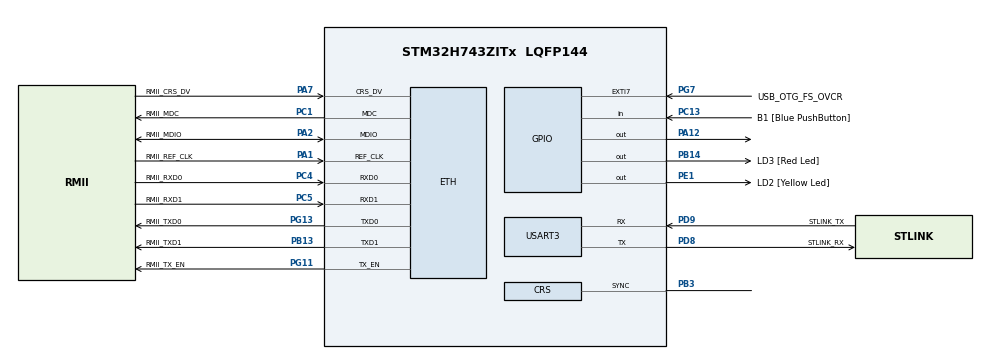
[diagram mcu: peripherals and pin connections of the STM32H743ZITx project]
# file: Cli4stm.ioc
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CORTEX_M7.AccessPermission-Cortex_Memory_Protection_Unit_Region0_Settings=MPU_REGION_FULL_ACCESS
CORTEX_M7.AccessPermission-Cortex_Memory_Protection_Unit_Region1_Settings=MPU_REGION_FULL_ACCESS
CORTEX_M7.BaseAddress-Cortex_Memory_Protection_Unit_Region0_Settings=0x30040000
CORTEX_M7.BaseAddress-Cortex_Memory_Protection_Unit_Region1_Settings=0x30040000
CORTEX_M7.CPU_DCache=Enabled
CORTEX_M7.CPU_ICache=Enabled
CORTEX_M7.DisableExec-Cortex_Memory_Protection_Unit_Region0_Settings=MPU_INSTRUCTION_ACCESS_DISABLE
CORTEX_M7.DisableExec-Cortex_Memory_Protection_Unit_Region1_Settings=MPU_INSTRUCTION_ACCESS_DISABLE
CORTEX_M7.Enable-Cortex_Memory_Protection_Unit_Region0_Settings=MPU_REGION_ENABLE
CORTEX_M7.Enable-Cortex_Memory_Protection_Unit_Region1_Settings=MPU_REGION_ENABLE
CORTEX_M7.IsBufferable-Cortex_Memory_Protection_Unit_Region1_Settings=MPU_ACCESS_BUFFERABLE
CORTEX_M7.IsShareable-Cortex_Memory_Protection_Unit_Region1_Settings=MPU_ACCESS_SHAREABLE
CORTEX_M7.MPU_Control=MPU_PRIVILEGED_DEFAULT
CORTEX_M7.Size-Cortex_Memory_Protection_Unit_Region0_Settings=MPU_REGION_SIZE_32KB
CORTEX_M7.Size-Cortex_Memory_Protection_Unit_Region1_Settings=MPU_REGION_SIZE_256B
CORTEX_M7.TypeExtField-Cortex_Memory_Protection_Unit_Region0_Settings=MPU_TEX_LEVEL1
ETH.MediaInterface=HAL_ETH_RMII_MODE
FREERTOS.Queues01=queueRxUart3,64,uint8_t,0,Static,rxUart3Buffer,rxUart3ControlBlock
FREERTOS.Tasks01=defaultTask,0,256,StartDefaultTask,Default,NULL,Dynamic,NULL,NULL;cliSerialTask,-3,256,StartCliTaskSerial,As external,&huart3,Dynamic,NULL,NULL;cliUdpTask,-3,256,StartCliTaskUdp,As external,NULL,Dynamic,NULL,NULL
FREERTOS.configENABLE_FPU=0
FREERTOS.configMINIMAL_STACK_SIZE=256
FREERTOS.configTOTAL_HEAP_SIZE=100000
FREERTOS.configUSE_NEWLIB_REENTRANT=1
FREERTOS.configUSE_PREEMPTION=1
LWIP.BSP.number=1
LWIP.GATEWAY_ADDRESS=192.168.014.001
LWIP.IP_ADDRESS=192.168.014.002
LWIP.LWIP_DHCP=0
LWIP.MEM_SIZE=1600
LWIP.NETMASK_ADDRESS=255.255.255.000
LWIP.Version=v2.1.2_Cube
LWIP0.BSP.STBoard=false
LWIP0.BSP.api=BSP_COMPONENT_DRIVER
LWIP0.BSP.component=LAN8742
LWIP0.BSP.i2caddr=0
LWIP0.BSP.instance=LAN8742
LWIP0.BSP.name=Driver_PHY
LWIP0.BSP.solution=LAN8742
Mcu.Family=STM32H7
Mcu.Name=STM32H743ZITx
Mcu.Package=LQFP144
Mcu.UserConstants=_GNU_SOURCE,1
NVIC.ETH_IRQn=true\:5\:0\:false\:false\:true\:true\:true\:true
NVIC.EXTI9_5_IRQn=true\:5\:0\:false\:false\:true\:true\:true\:true
NVIC.PriorityGroup=NVIC_PRIORITYGROUP_4
NVIC.TIM17_IRQn=true\:0\:0\:false\:false\:true\:false\:false\:true
NVIC.TimeBase=TIM17_IRQn
NVIC.TimeBaseIP=TIM17
NVIC.USART3_IRQn=true\:5\:0\:false\:false\:true\:true\:true\:true
PA1.GPIO_Label=RMII_REF_CLK
PA1.GPIO_Speed=GPIO_SPEED_FREQ_VERY_HIGH
PA1.Mode=RMII
PA1.Signal=ETH_REF_CLK
PA12.Signal=GPIO_Output
PA2.GPIO_Label=RMII_MDIO
PA2.GPIO_Speed=GPIO_SPEED_FREQ_VERY_HIGH
PA2.Mode=RMII
PA2.Signal=ETH_MDIO
PA7.GPIO_Label=RMII_CRS_DV
PA7.GPIO_Speed=GPIO_SPEED_FREQ_VERY_HIGH
PA7.Mode=RMII
PA7.Signal=ETH_CRS_DV
PB13.GPIO_Label=RMII_TXD1
PB13.GPIO_Speed=GPIO_SPEED_FREQ_VERY_HIGH
PB13.Mode=RMII
PB13.Signal=ETH_TXD1
PB14.GPIO_Label=LD3 [Red Led]
PB14.GPIO_Speed=GPIO_SPEED_FREQ_VERY_HIGH
PB14.PinState=GPIO_PIN_RESET
PB14.Signal=GPIO_Output
PB3\ (JTDO/TRACESWO).Mode=CRS SYNC Source GPIO
PB3\ (JTDO/TRACESWO).Signal=CRS_SYNC
PC1.GPIO_Label=RMII_MDC
PC1.GPIO_Speed=GPIO_SPEED_FREQ_LOW
PC1.Mode=RMII
PC1.Signal=ETH_MDC
PC13.GPIO_Label=B1 [Blue PushButton]
PC13.Signal=GPIO_Input
PC14-OSC32_IN\ (OSC32_IN).Mode=LSE-External-Oscillator
PC14-OSC32_IN\ (OSC32_IN).Signal=RCC_OSC32_IN
PC15-OSC32_OUT\ (OSC32_OUT).Mode=LSE-External-Oscillator
PC15-OSC32_OUT\ (OSC32_OUT).Signal=RCC_OSC32_OUT
PC4.GPIO_Label=RMII_RXD0
PC4.GPIO_Speed=GPIO_SPEED_FREQ_VERY_HIGH
PC4.Mode=RMII
PC4.Signal=ETH_RXD0
PC5.GPIO_Label=RMII_RXD1
PC5.GPIO_Speed=GPIO_SPEED_FREQ_VERY_HIGH
PC5.Mode=RMII
PC5.Signal=ETH_RXD1
PD8.GPIO_Label=STLINK_RX
PD8.Mode=Asynchronous
PD8.Signal=USART3_TX
PD9.GPIO_Label=STLINK_TX
PD9.Mode=Asynchronous
PD9.Signal=USART3_RX
PE1.GPIO_Label=LD2 [Yellow Led]
PE1.GPIO_Speed=GPIO_SPEED_FREQ_VERY_HIGH
PE1.Signal=GPIO_Output
PG11.GPIO_Label=RMII_TX_EN
PG11.GPIO_Speed=GPIO_SPEED_FREQ_VERY_HIGH
PG11.Mode=RMII
PG11.Signal=ETH_TX_EN
PG13.GPIO_Label=RMII_TXD0
PG13.GPIO_Speed=GPIO_SPEED_FREQ_VERY_HIGH
PG13.Mode=RMII
PG13.Signal=ETH_TXD0
PG7.GPIO_Label=USB_OTG_FS_OVCR
PG7.Signal=GPXTI7
PH0-OSC_IN\ (PH0).GPIO_Label=MCO
PH0-OSC_IN\ (PH0).Mode=HSE-External-Oscillator
PH0-OSC_IN\ (PH0).Signal=RCC_OSC_IN
PH1-OSC_OUT\ (PH1).Mode=HSE-External-Oscillator
PH1-OSC_OUT\ (PH1).Signal=RCC_OSC_OUT
ProjectManager.HeapSize=0x200
ProjectManager.StackSize=0x400
ProjectManager.TargetToolchain=STM32CubeIDE
RCC.ADCFreq_Value=129000000
RCC.APB1Freq_Value=100000000
RCC.APB2Freq_Value=100000000
RCC.APB3Freq_Value=100000000
RCC.APB4Freq_Value=100000000
RCC.CortexFreq_Value=400000000
RCC.D1PPRE=RCC_APB3_DIV2
RCC.D2PPRE1=RCC_APB1_DIV2
RCC.D2PPRE2=RCC_APB2_DIV2
RCC.D3PPRE=RCC_APB4_DIV2
RCC.DIVM1=4
RCC.DIVN1=50
RCC.DIVQ1=4
RCC.HCLKFreq_Value=200000000
RCC.HPRE=RCC_HCLK_DIV2
RCC.HSE_VALUE=25000000
RCC.PLL2FRACN=0
RCC.PLL3FRACN=0
RCC.PLLFRACN=0
RCC.PLLSourceVirtual=RCC_PLLSOURCE_HSI
RCC.PWR_Regulator_Voltage_Scale=PWR_REGULATOR_VOLTAGE_SCALE1
RCC.SYSCLKFreq_VALUE=400000000
RCC.SYSCLKSource=RCC_SYSCLKSOURCE_PLLCLK
RCC.USBFreq_Value=200000000
USART3.VirtualMode-Asynchronous=VM_ASYNC
VP_FREERTOS_VS_CMSIS_V1.Mode=CMSIS_V1
VP_HRTIM_VS_hrtimMasterTimerNoOutput.Mode=MasterTimer
VP_LWIP_VS_Enabled.Mode=Enabled
VP_SYS_VS_tim17.Mode=TIM17
board=NUCLEO-H743ZI2

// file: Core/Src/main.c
/* USER CODE BEGIN Header */
/**
  ******************************************************************************
  * @file           : main.c
  * @brief          : Main program body
  ******************************************************************************
  * @attention
  *
  * <h2><center>&copy; Copyright (c) 2021 STMicroelectronics.
  * All rights reserved.</center></h2>
  *
  * This software component is licensed by ST under BSD 3-Clause license,
  * the "License"; You may not use this file except in compliance with the
  * License. You may obtain a copy of the License at:
  *                        opensource.org/licenses/BSD-3-Clause
  *
  ******************************************************************************
  */
/* USER CODE END Header */
#include "main.h"
#include "cmsis_os.h"
#include "lwip.h"
#include "cliTaskTcp.h"

HRTIM_HandleTypeDef hhrtim;

UART_HandleTypeDef huart3;

osThreadId defaultTaskHandle;
osThreadId cliSerialTaskHandle;
osThreadId cliUdpTaskHandle;
osMessageQId queueRxUart3Handle;
uint8_t rxUart3Buffer[ 64 * sizeof( uint8_t ) ];
osStaticMessageQDef_t rxUart3ControlBlock;

void SystemClock_Config(void);
static void MPU_Config(void);
static void MX_GPIO_Init(void);
static void MX_USART3_UART_Init(void);
static void MX_HRTIM_Init(void);
void StartDefaultTask(void const * argument);
extern void StartCliTaskSerial(void const * argument);
extern void StartCliTaskUdp(void const * argument);

int main(void)
{

  /* MPU Configuration--------------------------------------------------------*/
  MPU_Config();

  /* Enable I-Cache---------------------------------------------------------*/
  SCB_EnableICache();

  /* Enable D-Cache---------------------------------------------------------*/
  SCB_EnableDCache();

  /* MCU Configuration--------------------------------------------------------*/

  /* Reset of all peripherals, Initializes the Flash interface and the Systick. */
  HAL_Init();

  /* Configure the system clock */
  SystemClock_Config();

  /* Initialize all configured peripherals */
  MX_GPIO_Init();
  MX_USART3_UART_Init();
  MX_HRTIM_Init();

  /* Create the queue(s) */
  /* definition and creation of queueRxUart3 */
  osMessageQStaticDef(queueRxUart3, 64, uint8_t, rxUart3Buffer, &rxUart3ControlBlock);
  queueRxUart3Handle = osMessageCreate(osMessageQ(queueRxUart3), NULL);

  /* Create the thread(s) */
  /* definition and creation of defaultTask */
  osThreadDef(defaultTask, StartDefaultTask, osPriorityNormal, 0, 256);
  defaultTaskHandle = osThreadCreate(osThread(defaultTask), NULL);

  /* definition and creation of cliSerialTask */
  osThreadDef(cliSerialTask, StartCliTaskSerial, osPriorityIdle, 0, 256);
  cliSerialTaskHandle = osThreadCreate(osThread(cliSerialTask), (void*) &huart3);

  /* definition and creation of cliUdpTask */
  osThreadDef(cliUdpTask, StartCliTaskUdp, osPriorityIdle, 0, 256);
  cliUdpTaskHandle = osThreadCreate(osThread(cliUdpTask), NULL);

  /* Start scheduler */
  osKernelStart();

  /* We should never get here as control is now taken by the scheduler */
  /* Infinite loop */
  while (1)
  {

  }
}

void SystemClock_Config(void)
{
  RCC_OscInitTypeDef RCC_OscInitStruct = {0};
  RCC_ClkInitTypeDef RCC_ClkInitStruct = {0};
  RCC_CRSInitTypeDef RCC_CRSInitStruct = {0};

  /** Supply configuration update enable
  */
  HAL_PWREx_ConfigSupply(PWR_LDO_SUPPLY);
  /** Configure the main internal regulator output voltage
  */
  __HAL_PWR_VOLTAGESCALING_CONFIG(PWR_REGULATOR_VOLTAGE_SCALE1);

  while(!__HAL_PWR_GET_FLAG(PWR_FLAG_VOSRDY)) {}
  /** Initializes the RCC Oscillators according to the specified parameters
  * in the RCC_OscInitTypeDef structure.
  */
  RCC_OscInitStruct.OscillatorType = RCC_OSCILLATORTYPE_HSI48|RCC_OSCILLATORTYPE_HSI;
  RCC_OscInitStruct.HSIState = RCC_HSI_DIV1;
  RCC_OscInitStruct.HSICalibrationValue = RCC_HSICALIBRATION_DEFAULT;
  RCC_OscInitStruct.HSI48State = RCC_HSI48_ON;
  RCC_OscInitStruct.PLL.PLLState = RCC_PLL_ON;
  RCC_OscInitStruct.PLL.PLLSource = RCC_PLLSOURCE_HSI;
  RCC_OscInitStruct.PLL.PLLM = 4;
  RCC_OscInitStruct.PLL.PLLN = 50;
  RCC_OscInitStruct.PLL.PLLP = 2;
  RCC_OscInitStruct.PLL.PLLQ = 4;
  RCC_OscInitStruct.PLL.PLLR = 2;
  RCC_OscInitStruct.PLL.PLLRGE = RCC_PLL1VCIRANGE_3;
  RCC_OscInitStruct.PLL.PLLVCOSEL = RCC_PLL1VCOWIDE;
  RCC_OscInitStruct.PLL.PLLFRACN = 0;
  if (HAL_RCC_OscConfig(&RCC_OscInitStruct) != HAL_OK)
  {
    Error_Handler();
  }
  /** Initializes the CPU, AHB and APB buses clocks
  */
  RCC_ClkInitStruct.ClockType = RCC_CLOCKTYPE_HCLK|RCC_CLOCKTYPE_SYSCLK
                              |RCC_CLOCKTYPE_PCLK1|RCC_CLOCKTYPE_PCLK2
                              |RCC_CLOCKTYPE_D3PCLK1|RCC_CLOCKTYPE_D1PCLK1;
  RCC_ClkInitStruct.SYSCLKSource = RCC_SYSCLKSOURCE_PLLCLK;
  RCC_ClkInitStruct.SYSCLKDivider = RCC_SYSCLK_DIV1;
  RCC_ClkInitStruct.AHBCLKDivider = RCC_HCLK_DIV2;
  RCC_ClkInitStruct.APB3CLKDivider = RCC_APB3_DIV2;
  RCC_ClkInitStruct.APB1CLKDivider = RCC_APB1_DIV2;
  RCC_ClkInitStruct.APB2CLKDivider = RCC_APB2_DIV2;
  RCC_ClkInitStruct.APB4CLKDivider = RCC_APB4_DIV2;

  if (HAL_RCC_ClockConfig(&RCC_ClkInitStruct, FLASH_LATENCY_2) != HAL_OK)
  {
    Error_Handler();
  }
  /** Enable the SYSCFG APB clock
  */
  __HAL_RCC_CRS_CLK_ENABLE();
  /** Configures CRS
  */
  RCC_CRSInitStruct.Prescaler = RCC_CRS_SYNC_DIV1;
  RCC_CRSInitStruct.Source = RCC_CRS_SYNC_SOURCE_PIN;
  RCC_CRSInitStruct.Polarity = RCC_CRS_SYNC_POLARITY_RISING;
  RCC_CRSInitStruct.ReloadValue = __HAL_RCC_CRS_RELOADVALUE_CALCULATE(48000000,1);
  RCC_CRSInitStruct.ErrorLimitValue = 34;
  RCC_CRSInitStruct.HSI48CalibrationValue = 32;

  HAL_RCCEx_CRSConfig(&RCC_CRSInitStruct);
}

static void MX_HRTIM_Init(void)
{

  HRTIM_TimeBaseCfgTypeDef pTimeBaseCfg = {0};
  HRTIM_TimerCfgTypeDef pTimerCfg = {0};

  hhrtim.Instance = HRTIM1;
  hhrtim.Init.HRTIMInterruptResquests = HRTIM_IT_NONE;
  hhrtim.Init.SyncOptions = HRTIM_SYNCOPTION_NONE;
  if (HAL_HRTIM_Init(&hhrtim) != HAL_OK)
  {
    Error_Handler();
  }
  pTimeBaseCfg.Period = 0xFFFD;
  pTimeBaseCfg.RepetitionCounter = 0x00;
  pTimeBaseCfg.PrescalerRatio = HRTIM_PRESCALERRATIO_DIV1;
  pTimeBaseCfg.Mode = HRTIM_MODE_CONTINUOUS;
  if (HAL_HRTIM_TimeBaseConfig(&hhrtim, HRTIM_TIMERINDEX_MASTER, &pTimeBaseCfg) != HAL_OK)
  {
    Error_Handler();
  }
  pTimerCfg.InterruptRequests = HRTIM_MASTER_IT_NONE;
  pTimerCfg.DMARequests = HRTIM_MASTER_DMA_NONE;
  pTimerCfg.DMASrcAddress = 0x0000;
  pTimerCfg.DMADstAddress = 0x0000;
  pTimerCfg.DMASize = 0x1;
  pTimerCfg.HalfModeEnable = HRTIM_HALFMODE_DISABLED;
  pTimerCfg.StartOnSync = HRTIM_SYNCSTART_DISABLED;
  pTimerCfg.ResetOnSync = HRTIM_SYNCRESET_DISABLED;
  pTimerCfg.DACSynchro = HRTIM_DACSYNC_NONE;
  pTimerCfg.PreloadEnable = HRTIM_PRELOAD_DISABLED;
  pTimerCfg.UpdateGating = HRTIM_UPDATEGATING_INDEPENDENT;
  pTimerCfg.BurstMode = HRTIM_TIMERBURSTMODE_MAINTAINCLOCK;
  pTimerCfg.RepetitionUpdate = HRTIM_UPDATEONREPETITION_DISABLED;
  if (HAL_HRTIM_WaveformTimerConfig(&hhrtim, HRTIM_TIMERINDEX_MASTER, &pTimerCfg) != HAL_OK)
  {
    Error_Handler();
  }

}

static void MX_USART3_UART_Init(void)
{

  huart3.Instance = USART3;
  huart3.Init.BaudRate = 115200;
  huart3.Init.WordLength = UART_WORDLENGTH_8B;
  huart3.Init.StopBits = UART_STOPBITS_1;
  huart3.Init.Parity = UART_PARITY_NONE;
  huart3.Init.Mode = UART_MODE_TX_RX;
  huart3.Init.HwFlowCtl = UART_HWCONTROL_NONE;
  huart3.Init.OverSampling = UART_OVERSAMPLING_16;
  huart3.Init.OneBitSampling = UART_ONE_BIT_SAMPLE_DISABLE;
  huart3.Init.ClockPrescaler = UART_PRESCALER_DIV1;
  huart3.AdvancedInit.AdvFeatureInit = UART_ADVFEATURE_NO_INIT;
  if (HAL_UART_Init(&huart3) != HAL_OK)
  {
    Error_Handler();
  }
  if (HAL_UARTEx_SetTxFifoThreshold(&huart3, UART_TXFIFO_THRESHOLD_1_8) != HAL_OK)
  {
    Error_Handler();
  }
  if (HAL_UARTEx_SetRxFifoThreshold(&huart3, UART_RXFIFO_THRESHOLD_1_8) != HAL_OK)
  {
    Error_Handler();
  }
  if (HAL_UARTEx_DisableFifoMode(&huart3) != HAL_OK)
  {
    Error_Handler();
  }

}

static void MX_GPIO_Init(void)
{
  GPIO_InitTypeDef GPIO_InitStruct = {0};

  /* GPIO Ports Clock Enable */
  __HAL_RCC_GPIOC_CLK_ENABLE();
  __HAL_RCC_GPIOH_CLK_ENABLE();
  __HAL_RCC_GPIOA_CLK_ENABLE();
  __HAL_RCC_GPIOB_CLK_ENABLE();
  __HAL_RCC_GPIOD_CLK_ENABLE();
  __HAL_RCC_GPIOG_CLK_ENABLE();
  __HAL_RCC_GPIOE_CLK_ENABLE();

  /*Configure GPIO pin Output Level */
  HAL_GPIO_WritePin(LD3_GPIO_Port, LD3_Pin, GPIO_PIN_RESET);

  /*Configure GPIO pin Output Level */
  HAL_GPIO_WritePin(GPIOA, GPIO_PIN_12, GPIO_PIN_RESET);

  /*Configure GPIO pin Output Level */
  HAL_GPIO_WritePin(LD2_GPIO_Port, LD2_Pin, GPIO_PIN_RESET);

  /*Configure GPIO pin : B1_Pin */
  GPIO_InitStruct.Pin = B1_Pin;
  GPIO_InitStruct.Mode = GPIO_MODE_INPUT;
  GPIO_InitStruct.Pull = GPIO_NOPULL;
  HAL_GPIO_Init(B1_GPIO_Port, &GPIO_InitStruct);

  /*Configure GPIO pin : LD3_Pin */
  GPIO_InitStruct.Pin = LD3_Pin;
  GPIO_InitStruct.Mode = GPIO_MODE_OUTPUT_PP;
  GPIO_InitStruct.Pull = GPIO_NOPULL;
  GPIO_InitStruct.Speed = GPIO_SPEED_FREQ_VERY_HIGH;
  HAL_GPIO_Init(LD3_GPIO_Port, &GPIO_InitStruct);

  /*Configure GPIO pin : USB_OTG_FS_OVCR_Pin */
  GPIO_InitStruct.Pin = USB_OTG_FS_OVCR_Pin;
  GPIO_InitStruct.Mode = GPIO_MODE_IT_RISING;
  GPIO_InitStruct.Pull = GPIO_NOPULL;
  HAL_GPIO_Init(USB_OTG_FS_OVCR_GPIO_Port, &GPIO_InitStruct);

  /*Configure GPIO pin : PA12 */
  GPIO_InitStruct.Pin = GPIO_PIN_12;
  GPIO_InitStruct.Mode = GPIO_MODE_OUTPUT_PP;
  GPIO_InitStruct.Pull = GPIO_NOPULL;
  GPIO_InitStruct.Speed = GPIO_SPEED_FREQ_LOW;
  HAL_GPIO_Init(GPIOA, &GPIO_InitStruct);

  /*Configure GPIO pin : PB3 */
  GPIO_InitStruct.Pin = GPIO_PIN_3;
  GPIO_InitStruct.Mode = GPIO_MODE_AF_PP;
  GPIO_InitStruct.Pull = GPIO_NOPULL;
  GPIO_InitStruct.Speed = GPIO_SPEED_FREQ_LOW;
  GPIO_InitStruct.Alternate = GPIO_AF10_CRS_SYNC;
  HAL_GPIO_Init(GPIOB, &GPIO_InitStruct);

  /*Configure GPIO pin : LD2_Pin */
  GPIO_InitStruct.Pin = LD2_Pin;
  GPIO_InitStruct.Mode = GPIO_MODE_OUTPUT_PP;
  GPIO_InitStruct.Pull = GPIO_NOPULL;
  GPIO_InitStruct.Speed = GPIO_SPEED_FREQ_VERY_HIGH;
  HAL_GPIO_Init(LD2_GPIO_Port, &GPIO_InitStruct);

  /* EXTI interrupt init*/
  HAL_NVIC_SetPriority(EXTI9_5_IRQn, 5, 0);
  HAL_NVIC_EnableIRQ(EXTI9_5_IRQn);

}

void StartDefaultTask(void const * argument)
{
  /* init code for LWIP */
  MX_LWIP_Init();
  /* USER CODE BEGIN 5 */
  StartCliTcpServer();
  /* Infinite loop */
  for(;;)
  {
	osDelay(1);
  }
  /* USER CODE END 5 */
}

/* MPU Configuration */

void MPU_Config(void)
{
  MPU_Region_InitTypeDef MPU_InitStruct = {0};

  /* Disables the MPU */
  HAL_MPU_Disable();
  /** Initializes and configures the Region and the memory to be protected
  */
  MPU_InitStruct.Enable = MPU_REGION_ENABLE;
  MPU_InitStruct.Number = MPU_REGION_NUMBER0;
  MPU_InitStruct.BaseAddress = 0x30040000;
  MPU_InitStruct.Size = MPU_REGION_SIZE_32KB;
  MPU_InitStruct.SubRegionDisable = 0x0;
  MPU_InitStruct.TypeExtField = MPU_TEX_LEVEL1;
  MPU_InitStruct.AccessPermission = MPU_REGION_FULL_ACCESS;
  MPU_InitStruct.DisableExec = MPU_INSTRUCTION_ACCESS_DISABLE;
  MPU_InitStruct.IsShareable = MPU_ACCESS_NOT_SHAREABLE;
  MPU_InitStruct.IsCacheable = MPU_ACCESS_NOT_CACHEABLE;
  MPU_InitStruct.IsBufferable = MPU_ACCESS_NOT_BUFFERABLE;

  HAL_MPU_ConfigRegion(&MPU_InitStruct);
  /** Initializes and configures the Region and the memory to be protected
  */
  MPU_InitStruct.Number = MPU_REGION_NUMBER1;
  MPU_InitStruct.Size = MPU_REGION_SIZE_256B;
  MPU_InitStruct.TypeExtField = MPU_TEX_LEVEL0;
  MPU_InitStruct.IsShareable = MPU_ACCESS_SHAREABLE;
  MPU_InitStruct.IsBufferable = MPU_ACCESS_BUFFERABLE;

  HAL_MPU_ConfigRegion(&MPU_InitStruct);
  /* Enables the MPU */
  HAL_MPU_Enable(MPU_PRIVILEGED_DEFAULT);

}

void HAL_TIM_PeriodElapsedCallback(TIM_HandleTypeDef *htim)
{
  if (htim->Instance == TIM17) {
    HAL_IncTick();
  }
}

void Error_Handler(void)
{
  __disable_irq();
  while (1)
  {
  }
}

/************************ (C) COPYRIGHT STMicroelectronics *****END OF FILE****/
